# STM8L151G2 register map
Vendor: STMicroelectronics; Series: STM8L/STM8AL, low density; File version: 1.0
Ultra-low-power 8-bit MCU with 4 Kbytes Flash, 16 MHz CPU, integrated EEPROM
CPU: other r1p0, big endian, no MPU, no FPU, 4 interrupt priority bits
Registers are 8-bit, read-write, reset 0x0 unless marked. A register's access mark holds for its fields unless they carry their own. Offsets are from the block's base; lines under a group give offsets from that group; [hi:lo] are bit positions; {n}, {i} and the like mark numbered series; 'fields as' and 'values as' point back to an identical list; <NAME> marks a mode.

## Memory map
0x00004800 OPT blocks up to offset 0xD
0x00005000 PORTA size 0x5
0x00005005 PORTB size 0x5
0x0000500A PORTC size 0x5
0x0000500F PORTD size 0x5
0x00005014 PORTE size 0x5
0x00005019 PORTF size 0x5
0x00005050 FLASH size 0x5
0x00005070 DMA1 blocks up to offset 0x2B
0x0000509D REMAP size 0x3
0x000050A0 ITC_EXTI blocks up to offset 0xC
0x000050A6 WFE size 0x4
0x000050B0 RST size 0x2
0x000050B2 PWR size 0x2
0x000050C0 CLK blocks up to offset 0xD1
0x000050D3 WWDG size 0x2
0x000050E0 IWDG size 0x3
0x000050F0 BEEP blocks up to offset 0x4
0x00005140 RTC blocks up to offset 0x2E
0x00005200 SPI1 size 0x8
0x00005210 I2C1 size 0xF
0x00005230 USART1 size 0xB
0x00005250 TIM2 size 0x17
0x00005280 TIM3 size 0x17
0x000052E0 TIM4 size 0xA
0x000052FF IRTIM size 0x1
0x00005340 ADC1 size 0x12
0x00005431 RI blocks up to offset 0x27
0x00005440 COMP size 0x5
0x00007F00 CPU blocks up to offset 0x61
0x00007F70 ITC_SPR size 0x8
0x00007F80 SWIM size 0x1
0x00007F90 DM size 0xB

## Interrupts
1 Interrupt_IRQ1 (FLASH) — Interrupt_IRQ1 interrupt
2 Interrupt_IRQ2 (DM, DMA1) — Interrupt_IRQ2 interrupt
3 Interrupt_IRQ3 (DM, DMA1) — Interrupt_IRQ3 interrupt
4 Interrupt_IRQ4 (RTC) — Interrupt_IRQ4 interrupt
17 Interrupt_IRQ17 (CLK) — Interrupt_IRQ17 interrupt
18 Interrupt_IRQ18 (ADC1, COMP) — Interrupt_IRQ18 interrupt
19 Interrupt_IRQ19 (TIM2) — Interrupt_IRQ19 interrupt
20 Interrupt_IRQ20 (TIM2) — Interrupt_IRQ20 interrupt
21 Interrupt_IRQ21 (TIM3) — Interrupt_IRQ21 interrupt
22 Interrupt_IRQ22 (TIM3) — Interrupt_IRQ22 interrupt
23 Interrupt_IRQ23 (RI) — Interrupt_IRQ23 interrupt
25 Interrupt_IRQ25 (TIM4) — Interrupt_IRQ25 interrupt

## ADC1
Base 0x00005340
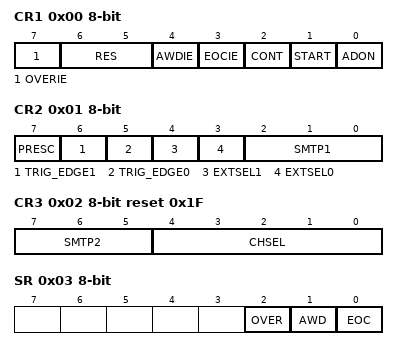
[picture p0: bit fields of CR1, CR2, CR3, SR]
0x00 CR1 — ADC1 configuration register 1
  [7] OVERIE, [6:5] RES, [4] AWDIE, [3] EOCIE, [2] CONT, [1] START, [0] ADON
0x01 CR2 — ADC1 configuration register 2
  [7] PRESC, [6] TRIG_EDGE1, [5] TRIG_EDGE0, [4] EXTSEL1, [3] EXTSEL0, [2:0] SMTP1
0x02 CR3 reset 0x1F — ADC1 configuration register 3
  [7:5] SMTP2, [4:0] CHSEL
0x03 SR — ADC1 status register
  [2] OVER, [1] AWD, [0] EOC
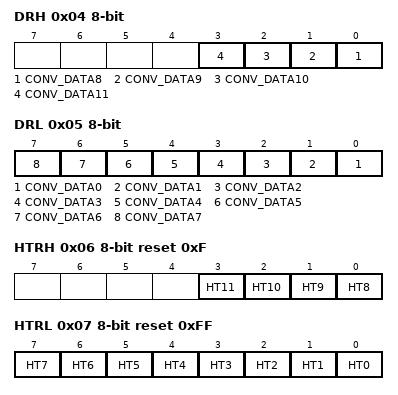
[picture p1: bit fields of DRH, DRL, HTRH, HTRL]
0x04 DRH — ADC1 data register high
  [n-8] CONV_DATA{n} (n=8..11)
0x05 DRL — ADC1 data register low
  [n] CONV_DATA{n} (n=0..7)
0x06 HTRH reset 0xF — ADC1 high threshold register high
  [n-8] HT{n} (n=8..11)
0x07 HTRL reset 0xFF — ADC1 high threshold register low
  [n] HT{n} (n=0..7)
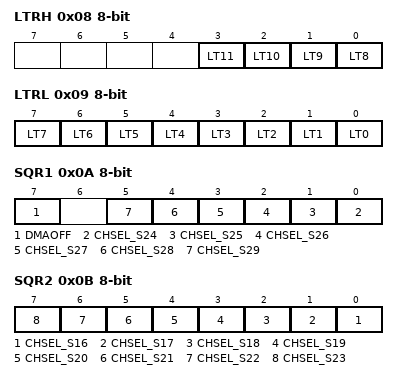
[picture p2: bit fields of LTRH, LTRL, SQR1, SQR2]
0x08 LTRH — ADC1 low threshold register high
  [n-8] LT{n} (n=8..11)
0x09 LTRL — ADC1 low threshold register low
  [n] LT{n} (n=0..7)
0x0A SQR1 — ADC1 channel sequence 1 register
  [7] DMAOFF, [n-24] CHSEL_S{n} (n=24..29)
0x0B SQR2 — ADC1 channel sequence 2 register
  [n-16] CHSEL_S{n} (n=16..23)
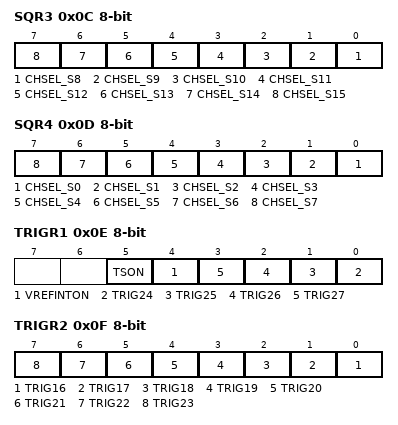
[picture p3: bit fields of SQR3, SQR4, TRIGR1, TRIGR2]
0x0C SQR3 — ADC1 channel sequence 3 register
  [n-8] CHSEL_S{n} (n=8..15)
0x0D SQR4 — ADC1 channel sequence 4 register
  [n] CHSEL_S{n} (n=0..7)
0x0E TRIGR1 — ADC1 trigger disable 1
  [5] TSON, [4] VREFINTON, [n-24] TRIG{n} (n=24..27)
0x0F TRIGR2 — ADC1 trigger disable 2
  [n-16] TRIG{n} (n=16..23)
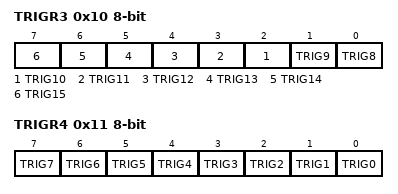
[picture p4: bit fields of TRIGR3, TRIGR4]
0x10 TRIGR3 — ADC1 trigger disable 3
  [n-8] TRIG{n} (n=8..15)
0x11 TRIGR4 — ADC1 trigger disable 4
  [n] TRIG{n} (n=0..7)

## BEEP
Base 0x000050F0
0x00 CSR1 — BEEP control/status register 1
  [0] MSR
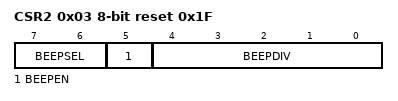
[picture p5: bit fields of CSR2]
0x03 CSR2 reset 0x1F — BEEP control/status register 2
  [7:6] BEEPSEL, [5] BEEPEN, [4:0] BEEPDIV

## CLK
Base 0x000050C0
0x00 CKDIVR reset 0x3 — Clock master divider register
  [2:0] CKM
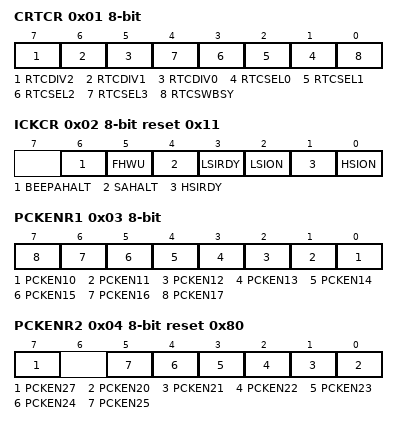
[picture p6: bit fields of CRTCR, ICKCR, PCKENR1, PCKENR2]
0x01 CRTCR — Clock RTC register
  [7] RTCDIV2, [6] RTCDIV1, [5] RTCDIV0, [n+1] RTCSEL{n} (n=0..3), [0] RTCSWBSY
0x02 ICKCR reset 0x11 — Internal clock control register
  [6] BEEPAHALT, [5] FHWU, [4] SAHALT, [3] LSIRDY, [2] LSION, [1] HSIRDY, [0] HSION
0x03 PCKENR1 — Peripheral clock gating register 1
  [n-10] PCKEN{n} (n=10..17)
0x04 PCKENR2 reset 0x80 — Peripheral clock gating register 2
  [7] PCKEN27, [n-20] PCKEN{n} (n=20..25)
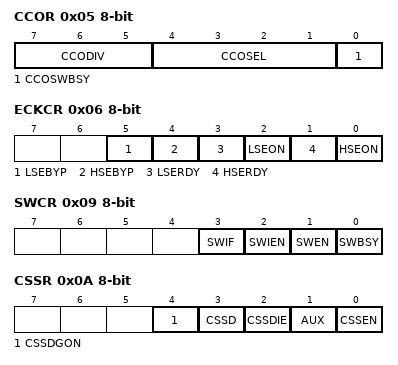
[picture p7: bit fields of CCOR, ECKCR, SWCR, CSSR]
0x05 CCOR — Configurable clock control register
  [7:5] CCODIV, [4:1] CCOSEL, [0] CCOSWBSY
0x06 ECKCR — External clock control register
  [5] LSEBYP, [4] HSEBYP, [3] LSERDY, [2] LSEON, [1] HSERDY, [0] HSEON
0x07 SCSR reset 0x1 — Clock master status register
  [7:0] CKM
0x08 SWR reset 0x1 — Clock master switch register
  [7:0] SWI
0x09 SWCR — Clock switch control register
  [3] SWIF, [2] SWIEN, [1] SWEN, [0] SWBSY
0x0A CSSR — Clock security system register
  [4] CSSDGON, [3] CSSD, [2] CSSDIE, [1] AUX, [0] CSSEN
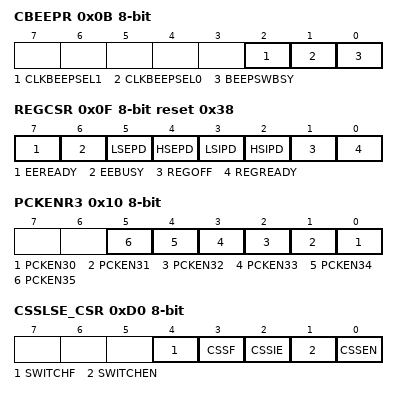
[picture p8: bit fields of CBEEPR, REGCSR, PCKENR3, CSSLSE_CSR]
0x0B CBEEPR — Clock BEEP register
  [2] CLKBEEPSEL1, [1] CLKBEEPSEL0, [0] BEEPSWBSY
0x0C HSICALR — HSI calibration register
  [7:0] HSICAL
0x0D HSITRIMR — HSI clock calibration trimming register
  [7:0] HSITRIM
0x0E HSIUNLCKR — HSI unlock register
  [7:0] HSIUNLCK
0x0F REGCSR reset 0x38 — Main regulator control status register
  [7] EEREADY, [6] EEBUSY, [5] LSEPD, [4] HSEPD, [3] LSIPD, [2] HSIPD, [1] REGOFF, [0] REGREADY
0x10 PCKENR3 — Peripheral clock gating register 3
  [n-30] PCKEN{n} (n=30..35)
0xD0 CSSLSE_CSR — CSS on LSE control and status register
  [4] SWITCHF, [3] CSSF, [2] CSSIE, [1] SWITCHEN, [0] CSSEN
